# nrf54h20_enga_application register map
Vendor: Nordic Semiconductor; Series: nRF54h; File version: 1
CPU: CM33 r0p4, little endian, MPU, FPU, 3 interrupt priority bits, 480 interrupts, 4 SAU regions
Registers are 32-bit, read-write, reset 0x0 unless marked. A register's access mark holds for its fields unless they carry their own. Offsets are from the block's base; [hi:lo] are bit positions; lines under a group give offsets from that group; 'fields as' and 'values as' point back to an identical list.

## GLOBAL_SPIS120_NS — SPI Slave 0
Base 0x4F8E5000
Same registers: GLOBAL_SPIS130_NS 0x4F9A5000 (alternate view of GLOBAL_SPIM130_NS), GLOBAL_SPIS131_NS 0x4F9A6000 (alternate view of GLOBAL_SPIM131_NS), GLOBAL_SPIS132_NS 0x4F9B5000 (alternate view of GLOBAL_SPIM132_NS), GLOBAL_SPIS133_NS 0x4F9B6000 (alternate view of GLOBAL_SPIM133_NS), GLOBAL_SPIS134_NS 0x4F9C5000 (alternate view of GLOBAL_SPIM134_NS), GLOBAL_SPIS135_NS 0x4F9C6000 (alternate view of GLOBAL_SPIM135_NS), GLOBAL_SPIS136_NS 0x4F9D5000 (alternate view of GLOBAL_SPIM136_NS), GLOBAL_SPIS137_NS 0x4F9D6000 (alternate view of GLOBAL_SPIM137_NS), GLOBAL_SPIS120_S 0x5F8E5000, GLOBAL_SPIS130_S 0x5F9A5000 (alternate view of GLOBAL_SPIM130_S), GLOBAL_SPIS131_S 0x5F9A6000 (alternate view of GLOBAL_SPIM131_S), GLOBAL_SPIS132_S 0x5F9B5000 (alternate view of GLOBAL_SPIM132_S), GLOBAL_SPIS133_S 0x5F9B6000 (alternate view of GLOBAL_SPIM133_S), GLOBAL_SPIS134_S 0x5F9C5000 (alternate view of GLOBAL_SPIM134_S), GLOBAL_SPIS135_S 0x5F9C6000 (alternate view of GLOBAL_SPIM135_S), GLOBAL_SPIS136_S 0x5F9D5000 (alternate view of GLOBAL_SPIM136_S), GLOBAL_SPIS137_S 0x5F9D6000 (alternate view of GLOBAL_SPIM137_S)
0x24 TASKS_ACQUIRE wo — Acquire SPI semaphore
  [0] TASKS_ACQUIRE
    1=Trigger task
0x28 TASKS_RELEASE wo — Release SPI semaphore, enabling the SPI slave to acquire it
  [0] TASKS_RELEASE
    1=Trigger task
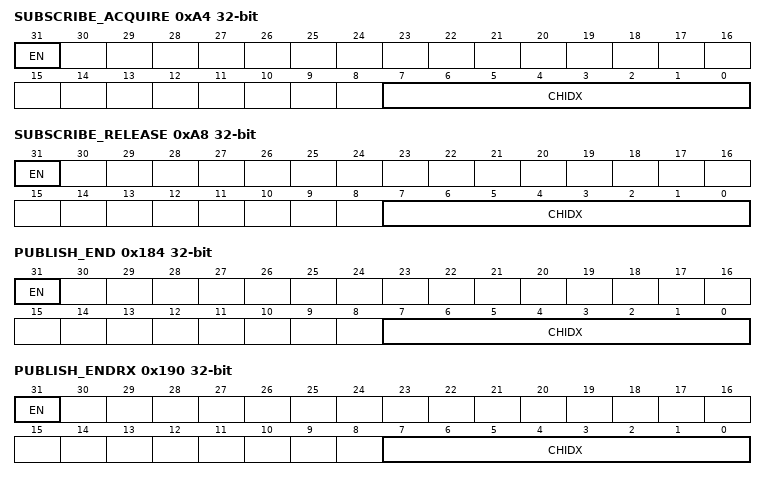
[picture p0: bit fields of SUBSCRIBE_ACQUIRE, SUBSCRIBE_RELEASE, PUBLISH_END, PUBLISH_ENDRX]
0xA4 SUBSCRIBE_ACQUIRE — Subscribe configuration for task ACQUIRE
  [31] EN
    0=Disabled (Disable subscription); 1=Enabled (Enable subscription)
  [7:0] CHIDX — DPPI channel that task ACQUIRE will subscribe to
0xA8 SUBSCRIBE_RELEASE — Subscribe configuration for task RELEASE
  [31] EN
    values as SUBSCRIBE_ACQUIRE.EN
  [7:0] CHIDX — DPPI channel that task RELEASE will subscribe to
0x104 EVENTS_END — Granted transaction completed
  [0] EVENTS_END
    0=NotGenerated (Event not generated); 1=Generated (Event generated)
0x110 EVENTS_ENDRX — End of RXD buffer reached
  [0] EVENTS_ENDRX
    values as EVENTS_END.EVENTS_END
0x128 EVENTS_ACQUIRED — Semaphore acquired
  [0] EVENTS_ACQUIRED
    values as EVENTS_END.EVENTS_END
0x174 EVENTS_RXBUSERROR — This event is generated if an error occurs during the bus transfer. This event is generated on an AHB / AXI error response.
  [0] EVENTS_RXBUSERROR
    values as EVENTS_END.EVENTS_END
0x178 EVENTS_TXBUSERROR — This event is generated if an error occurs during the bus transfer. This event is generated on an AHB / AXI error response.
  [0] EVENTS_TXBUSERROR
    values as EVENTS_END.EVENTS_END
0x184 PUBLISH_END — Publish configuration for event END
  [31] EN
    0=Disabled (Disable publishing); 1=Enabled (Enable publishing)
  [7:0] CHIDX — DPPI channel that event END will publish to
0x190 PUBLISH_ENDRX — Publish configuration for event ENDRX
  [31] EN
    values as PUBLISH_END.EN
  [7:0] CHIDX — DPPI channel that event ENDRX will publish to
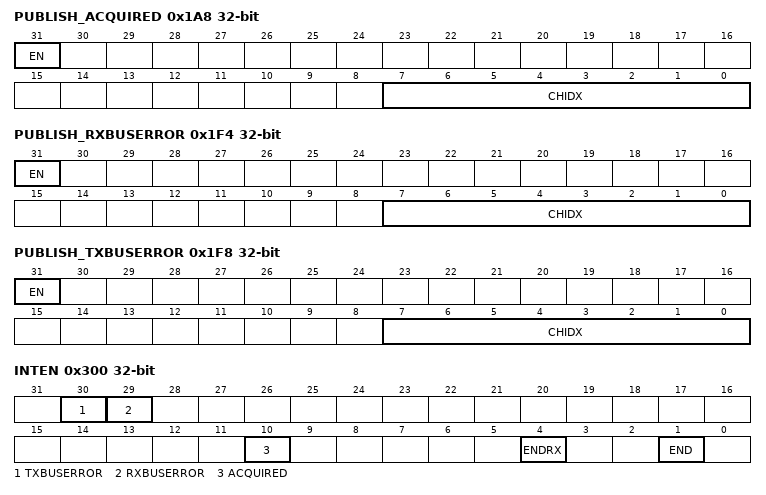
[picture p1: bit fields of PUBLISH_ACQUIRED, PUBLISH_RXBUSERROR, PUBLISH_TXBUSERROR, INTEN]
0x1A8 PUBLISH_ACQUIRED — Publish configuration for event ACQUIRED
  [31] EN
    values as PUBLISH_END.EN
  [7:0] CHIDX — DPPI channel that event ACQUIRED will publish to
0x1F4 PUBLISH_RXBUSERROR — Publish configuration for event RXBUSERROR
  [31] EN
    values as PUBLISH_END.EN
  [7:0] CHIDX — DPPI channel that event RXBUSERROR will publish to
0x1F8 PUBLISH_TXBUSERROR — Publish configuration for event TXBUSERROR
  [31] EN
    values as PUBLISH_END.EN
  [7:0] CHIDX — DPPI channel that event TXBUSERROR will publish to
0x200 SHORTS — Shortcuts between local events and tasks
  [2] END_ACQUIRE — Shortcut between event END and task ACQUIRE
    0=Disabled (Disable shortcut); 1=Enabled (Enable shortcut)
0x300 INTEN — Enable or disable interrupt
  [all] fields
    0=Disabled; 1=Enabled
  [30] TXBUSERROR — Enable or disable interrupt for event TXBUSERROR
  [29] RXBUSERROR — Enable or disable interrupt for event RXBUSERROR
  [10] ACQUIRED — Enable or disable interrupt for event ACQUIRED
  [4] ENDRX — Enable or disable interrupt for event ENDRX
  [1] END — Enable or disable interrupt for event END
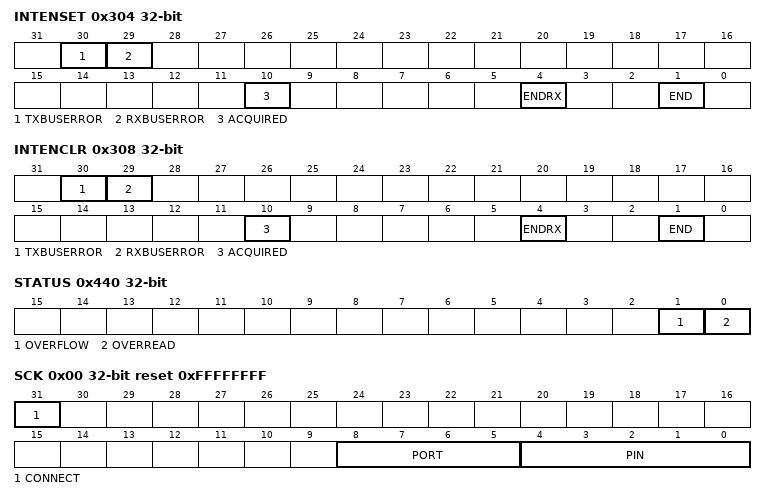
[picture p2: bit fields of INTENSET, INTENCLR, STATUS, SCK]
0x304 INTENSET — Enable interrupt
  [all] fields
    on read: 0=Disabled (Read: Disabled); 1=Enabled (Read: Enabled) | on write: 1=Set (Enable)
  [30] TXBUSERROR — Write '1' to enable interrupt for event TXBUSERROR
  [29] RXBUSERROR — Write '1' to enable interrupt for event RXBUSERROR
  [10] ACQUIRED — Write '1' to enable interrupt for event ACQUIRED
  [4] ENDRX — Write '1' to enable interrupt for event ENDRX
  [1] END — Write '1' to enable interrupt for event END
0x308 INTENCLR — Disable interrupt
  [all] fields
    on read: 0=Disabled (Read: Disabled); 1=Enabled (Read: Enabled) | on write: 1=Clear (Disable)
  [30] TXBUSERROR — Write '1' to disable interrupt for event TXBUSERROR
  [29] RXBUSERROR — Write '1' to disable interrupt for event RXBUSERROR
  [10] ACQUIRED — Write '1' to disable interrupt for event ACQUIRED
  [4] ENDRX — Write '1' to disable interrupt for event ENDRX
  [1] END — Write '1' to disable interrupt for event END
0x400 SEMSTAT ro reset 0x1 — Semaphore status register
  [1:0] SEMSTAT — Semaphore status
    0=Free (Semaphore is free); 1=CPU (Semaphore is assigned to CPU); 2=SPIS (Semaphore is assigned to SPI slave); 3=CPUPending (Semaphore is assigned to SPI but a handover to the CPU is pending)
0x440 STATUS — Status from last transaction
  [1] OVERFLOW — RX buffer overflow detected, and prevented
    on read: 0=NotPresent (Read: error not present); 1=Present (Read: error present) | on write: 1=Clear (Write: clear error on writing '1')
  [0] OVERREAD — TX buffer over-read detected, and prevented
    values as OVERFLOW
0x500 ENABLE — Enable SPI slave
  [3:0] ENABLE — Enable or disable SPI slave
    0=Disabled (Disable SPI slave); 2=Enabled (Enable SPI slave)
0x508 PSEL group — Unspecified
  0x00 SCK reset 0xFFFFFFFF — Pin select for SCK
    [31] CONNECT — Connection
      1=Disconnected; 0=Connected
    [8:5] PORT — Port number
    [4:0] PIN — Pin number
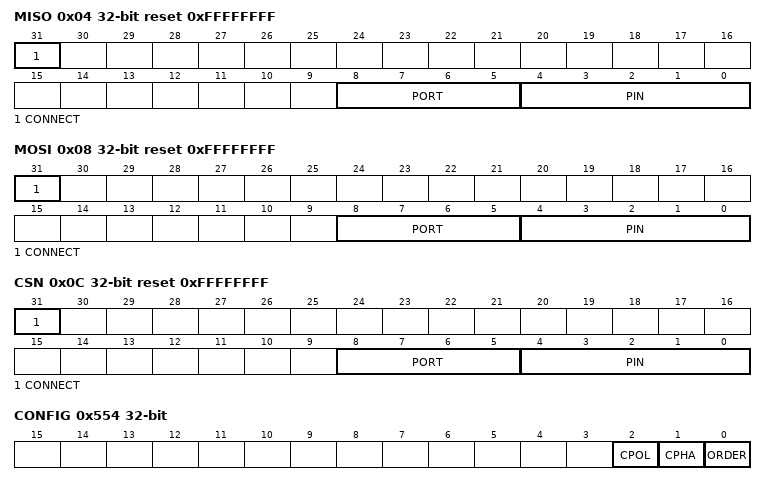
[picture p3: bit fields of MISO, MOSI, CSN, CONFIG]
  0x04 MISO reset 0xFFFFFFFF — Pin select for MISO signal
    fields as PSEL.SCK
  0x08 MOSI reset 0xFFFFFFFF — Pin select for MOSI signal
    fields as PSEL.SCK
  0x0C CSN reset 0xFFFFFFFF — Pin select for CSN signal
    fields as PSEL.SCK
0x534 RXD group — Unspecified
  0x00 PTR — RXD data pointer
  0x04 MAXCNT — Maximum number of bytes in receive buffer
    [14:0] MAXCNT
  0x08 AMOUNT ro — Number of bytes received in last granted transaction
    [14:0] AMOUNT — Number of bytes received in the last granted transaction
  0x0C LIST — EasyDMA list type
    [1:0] LIST — List type
      0=Disabled (Disable EasyDMA list); 1=ArrayList (Use array list)
0x544 TXD group — Unspecified
  0x00 PTR — TXD data pointer
  0x04 MAXCNT — Maximum number of bytes in transmit buffer
    [14:0] MAXCNT
  0x08 AMOUNT ro — Number of bytes transmitted in last granted transaction
    [14:0] AMOUNT
  0x0C LIST — EasyDMA list type
    fields as RXD.LIST
0x554 CONFIG — Configuration register
  [2] CPOL — Serial clock (SCK) polarity
    0=ActiveHigh; 1=ActiveLow
  [1] CPHA — Serial clock (SCK) phase
    0=Leading (Sample on leading edge of clock, shift serial data on trailing edge); 1=Trailing (Sample on trailing edge of clock, shift serial data on leading edge)
  [0] ORDER — Bit order
    0=MsbFirst (Most significant bit shifted out first); 1=LsbFirst (Least significant bit shifted out first)
0x55C DEF — Default character. Character clocked out in case of an ignored transaction.
  [7:0] DEF
0x5B0 DMA group — Unspecified
  0x00 RX group — Unspecified
    0x00 TERMINATEONBUSERROR — Terminate the transaction if a BUSERROR event is detected.
      [0] ENABLE
        0=Disabled; 1=Enabled
    0x04 BUSERRORADDRESS ro — Address of transaction that generated the last BUSERROR event.
      [31:0] ADDRESS
  0x08 TX group — Unspecified
    0x00 TERMINATEONBUSERROR — Terminate the transaction if a BUSERROR event is detected.
      [0] ENABLE
        0=Disabled; 1=Enabled
    0x04 BUSERRORADDRESS ro — Address of transaction that generated the last BUSERROR event.
      [31:0] ADDRESS
0x5C0 ORC — Over-read character
  [7:0] ORC — Over-read character. Character clocked out after an over-read of the transmit buffer.
